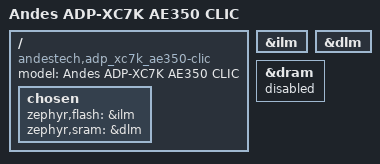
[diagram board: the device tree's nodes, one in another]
/*
 * Copyright (c) 2026 Andes Technology Corporation
 *
 * SPDX-License-Identifier: Apache-2.0
 */

/dts-v1/;

#include <andes/andes_v5_ae350_d23_clic.dtsi>
#include "adp_xc7k_common.dtsi"
#include <zephyr/dt-bindings/input/input-event-codes.h>

/ {
	compatible = "andestech,adp_xc7k_ae350-clic";
	model = "Andes ADP-XC7K AE350 CLIC";

	chosen {
		zephyr,flash = &ilm;
		zephyr,sram = &dlm;
	};
};

&ilm {
	status = "okay";
};

&dlm {
	status = "okay";
};

&dram {
	status = "disabled";
};
